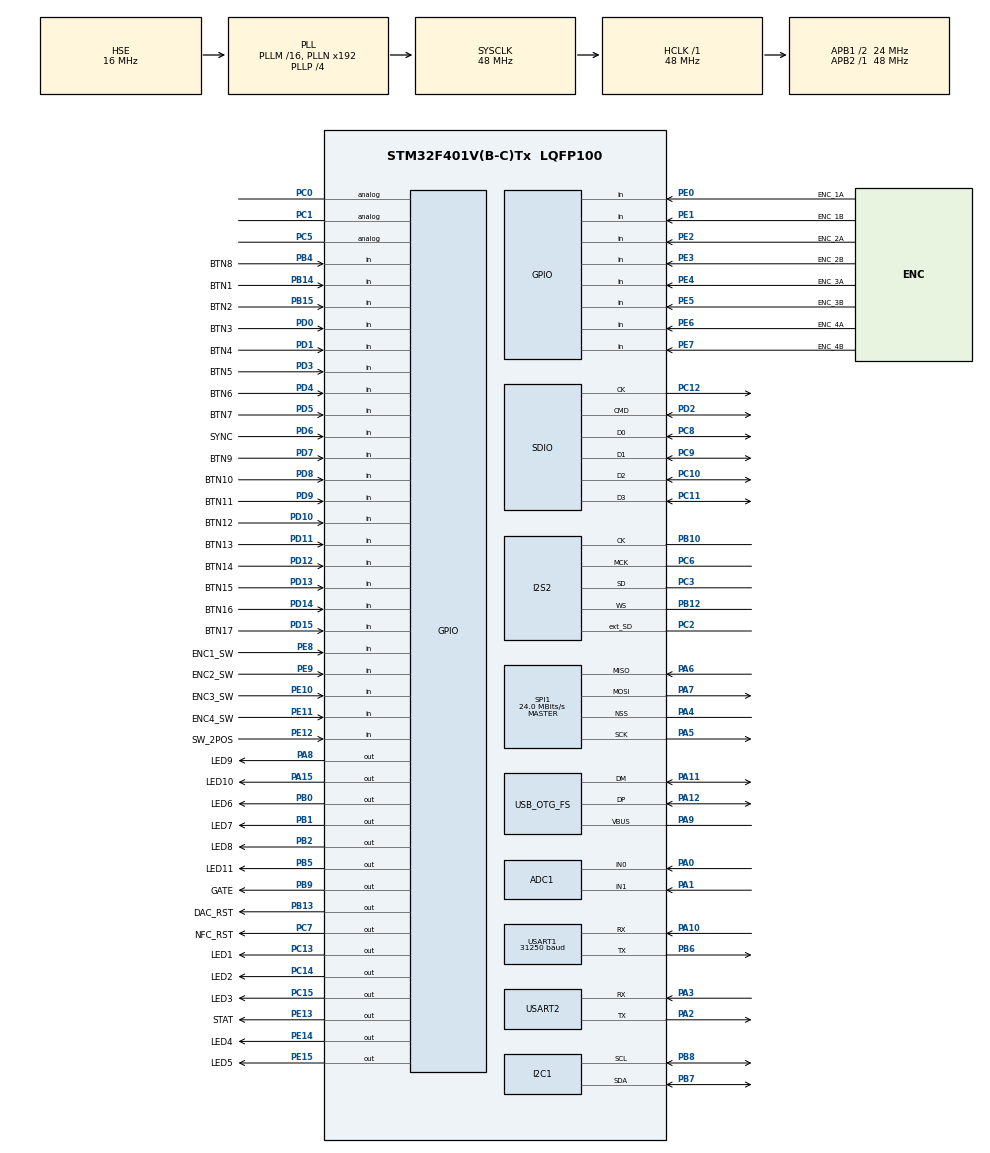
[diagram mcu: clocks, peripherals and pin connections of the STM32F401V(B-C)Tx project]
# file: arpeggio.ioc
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ADC1.Channel-0\#ChannelRegularConversion=ADC_CHANNEL_0
ADC1.Channel-1\#ChannelRegularConversion=ADC_CHANNEL_1
ADC1.ClockPrescaler=ADC_CLOCKPRESCALER_PCLK_DIV2
ADC1.ContinuousConvMode=DISABLE
ADC1.DMAContinuousRequests=DISABLE
ADC1.DataAlign=ADC_DATAALIGN_RIGHT
ADC1.DiscontinuousConvMode=DISABLE
ADC1.EOCSelection=EOC_SEQ_CONV
ADC1.EnableAnalogWatchDog=false
ADC1.ExternalTrigConvEdge=ADC_EXTERNALTRIGCONVEDGE_NONE
ADC1.InjNumberOfConversion=0
ADC1.NbrOfConversion=2
ADC1.NbrOfConversionFlag=1
ADC1.Rank-0\#ChannelRegularConversion=1
ADC1.Rank-1\#ChannelRegularConversion=2
ADC1.Resolution=ADC_RESOLUTION12b
ADC1.SamplingTime-0\#ChannelRegularConversion=ADC_SAMPLETIME_15CYCLES
ADC1.SamplingTime-1\#ChannelRegularConversion=ADC_SAMPLETIME_15CYCLES
ADC1.ScanConvMode=ENABLE
ADC1.master=1
Dma.ADC1.4.Channel=DMA_CHANNEL_0
Dma.ADC1.4.Direction=DMA_PERIPH_TO_MEMORY
Dma.ADC1.4.FIFOMode=DMA_FIFOMODE_DISABLE
Dma.ADC1.4.Instance=DMA2_Stream4
Dma.ADC1.4.MemDataAlignment=DMA_MDATAALIGN_HALFWORD
Dma.ADC1.4.MemInc=DMA_MINC_ENABLE
Dma.ADC1.4.Mode=DMA_CIRCULAR
Dma.ADC1.4.PeriphDataAlignment=DMA_PDATAALIGN_HALFWORD
Dma.ADC1.4.PeriphInc=DMA_PINC_DISABLE
Dma.ADC1.4.Priority=DMA_PRIORITY_MEDIUM
Dma.I2C1_RX.0.Channel=DMA_CHANNEL_1
Dma.I2C1_RX.0.Direction=DMA_PERIPH_TO_MEMORY
Dma.I2C1_RX.0.FIFOMode=DMA_FIFOMODE_DISABLE
Dma.I2C1_RX.0.Instance=DMA1_Stream0
Dma.I2C1_RX.0.MemDataAlignment=DMA_MDATAALIGN_BYTE
Dma.I2C1_RX.0.MemInc=DMA_MINC_ENABLE
Dma.I2C1_RX.0.Mode=DMA_NORMAL
Dma.I2C1_RX.0.PeriphDataAlignment=DMA_PDATAALIGN_BYTE
Dma.I2C1_RX.0.PeriphInc=DMA_PINC_DISABLE
Dma.I2C1_RX.0.Priority=DMA_PRIORITY_HIGH
Dma.I2C1_TX.1.Channel=DMA_CHANNEL_1
Dma.I2C1_TX.1.Direction=DMA_MEMORY_TO_PERIPH
Dma.I2C1_TX.1.FIFOMode=DMA_FIFOMODE_DISABLE
Dma.I2C1_TX.1.Instance=DMA1_Stream6
Dma.I2C1_TX.1.MemDataAlignment=DMA_MDATAALIGN_BYTE
Dma.I2C1_TX.1.MemInc=DMA_MINC_ENABLE
Dma.I2C1_TX.1.Mode=DMA_NORMAL
Dma.I2C1_TX.1.PeriphDataAlignment=DMA_PDATAALIGN_BYTE
Dma.I2C1_TX.1.PeriphInc=DMA_PINC_DISABLE
Dma.I2C1_TX.1.Priority=DMA_PRIORITY_HIGH
Dma.Request0=I2C1_RX
Dma.Request1=I2C1_TX
Dma.Request2=SPI1_RX
Dma.Request3=SPI1_TX
Dma.Request4=ADC1
Dma.SPI1_RX.2.Channel=DMA_CHANNEL_3
Dma.SPI1_RX.2.Direction=DMA_PERIPH_TO_MEMORY
Dma.SPI1_RX.2.FIFOMode=DMA_FIFOMODE_DISABLE
Dma.SPI1_RX.2.Instance=DMA2_Stream0
Dma.SPI1_RX.2.MemDataAlignment=DMA_MDATAALIGN_BYTE
Dma.SPI1_RX.2.MemInc=DMA_MINC_ENABLE
Dma.SPI1_RX.2.Mode=DMA_NORMAL
Dma.SPI1_RX.2.PeriphDataAlignment=DMA_PDATAALIGN_BYTE
Dma.SPI1_RX.2.PeriphInc=DMA_PINC_DISABLE
Dma.SPI1_RX.2.Priority=DMA_PRIORITY_HIGH
Dma.SPI1_TX.3.Channel=DMA_CHANNEL_3
Dma.SPI1_TX.3.Direction=DMA_MEMORY_TO_PERIPH
Dma.SPI1_TX.3.FIFOMode=DMA_FIFOMODE_DISABLE
Dma.SPI1_TX.3.Instance=DMA2_Stream3
Dma.SPI1_TX.3.MemDataAlignment=DMA_MDATAALIGN_BYTE
Dma.SPI1_TX.3.MemInc=DMA_MINC_ENABLE
Dma.SPI1_TX.3.Mode=DMA_NORMAL
Dma.SPI1_TX.3.PeriphDataAlignment=DMA_PDATAALIGN_BYTE
Dma.SPI1_TX.3.PeriphInc=DMA_PINC_DISABLE
Dma.SPI1_TX.3.Priority=DMA_PRIORITY_HIGH
FREERTOS.INCLUDE_vTaskDelayUntil=1
FREERTOS.Tasks01=defaultTask,0,128,StartDefaultTask
FREERTOS.configUSE_TIMERS=1
I2S2.AudioFreq=I2S_AUDIOFREQ_44K
I2S2.DataFormat=I2S_DATAFORMAT_16B
I2S2.ErrorAudioFreq=-3.33 %
I2S2.FullDuplexMode=I2S_FULLDUPLEXMODE_ENABLE
I2S2.RealAudioFreq=42.534 KHz
Mcu.Family=STM32F4
Mcu.Name=STM32F401V(B-C)Tx
Mcu.Package=LQFP100
NVIC.DMA1_Stream0_IRQn=true\:5\:0\:false
NVIC.DMA1_Stream6_IRQn=true\:5\:0\:false
NVIC.DMA2_Stream0_IRQn=true\:5\:0\:false
NVIC.DMA2_Stream3_IRQn=true\:5\:0\:false
NVIC.DMA2_Stream4_IRQn=true\:5\:0\:false
NVIC.OTG_FS_IRQn=true\:5\:0\:false
NVIC.PriorityGroup=NVIC_PRIORITYGROUP_4
NVIC.USART1_IRQn=true\:5\:0\:false
PA0-WKUP.Signal=ADCx_IN0
PA1.Signal=ADCx_IN1
PA10.Mode=Asynchronous
PA10.Signal=USART1_RX
PA11.Mode=Device_Only
PA11.Signal=USB_OTG_FS_DM
PA12.Mode=Device_Only
PA12.Signal=USB_OTG_FS_DP
PA13.Mode=Trace-Asynchronous_SW
PA13.Signal=SYS_JTMS-SWDIO
PA14.Mode=Trace-Asynchronous_SW
PA14.Signal=SYS_JTCK-SWCLK
PA15.GPIO_Label=LED10
PA15.GPIO_ModeDefaultOutputPP=GPIO_MODE_OUTPUT_PP
PA15.GPIO_PuPd=GPIO_NOPULL
PA15.GPIO_Speed=GPIO_SPEED_LOW
PA15.Signal=GPIO_Output
PA2.Mode=Asynchronous
PA2.Signal=USART2_TX
PA3.Mode=Asynchronous
PA3.Signal=USART2_RX
PA4.Mode=NSS_Signal_Hard
PA4.Signal=SPI1_NSS
PA5.Mode=Full_Duplex_Master
PA5.Signal=SPI1_SCK
PA6.Mode=Full_Duplex_Master
PA6.Signal=SPI1_MISO
PA7.Mode=Full_Duplex_Master
PA7.Signal=SPI1_MOSI
PA8.GPIO_Label=LED9
PA8.GPIO_ModeDefaultOutputPP=GPIO_MODE_OUTPUT_PP
PA8.GPIO_PuPd=GPIO_NOPULL
PA8.GPIO_Speed=GPIO_SPEED_LOW
PA8.Signal=GPIO_Output
PA9.Mode=Activate_VBUS
PA9.Signal=USB_OTG_FS_VBUS
PB0.GPIO_Label=LED6
PB0.GPIO_ModeDefaultOutputPP=GPIO_MODE_OUTPUT_PP
PB0.GPIO_PuPd=GPIO_NOPULL
PB0.GPIO_Speed=GPIO_SPEED_LOW
PB0.Signal=GPIO_Output
PB1.GPIO_Label=LED7
PB1.GPIO_ModeDefaultOutputPP=GPIO_MODE_OUTPUT_PP
PB1.GPIO_PuPd=GPIO_NOPULL
PB1.GPIO_Speed=GPIO_SPEED_LOW
PB1.Signal=GPIO_Output
PB10.Mode=Full_Duplex_Master
PB10.Signal=I2S2_CK
PB12.Mode=Full_Duplex_Master
PB12.Signal=I2S2_WS
PB13.GPIO_Label=DAC_RST
PB13.Signal=GPIO_Output
PB14.GPIO_Label=BTN1
PB14.Signal=GPIO_Input
PB15.GPIO_Label=BTN2
PB15.Signal=GPIO_Input
PB2.GPIO_Label=LED8
PB2.GPIO_ModeDefaultOutputPP=GPIO_MODE_OUTPUT_PP
PB2.GPIO_PuPd=GPIO_NOPULL
PB2.GPIO_Speed=GPIO_SPEED_LOW
PB2.Signal=GPIO_Output
PB3.Mode=Trace-Asynchronous_SW
PB3.Signal=SYS_JTDO-SWO
PB4.GPIO_Label=BTN8
PB4.Signal=GPIO_Input
PB5.GPIO_Label=LED11
PB5.GPIO_ModeDefaultOutputPP=GPIO_MODE_OUTPUT_PP
PB5.GPIO_PuPd=GPIO_NOPULL
PB5.GPIO_Speed=GPIO_SPEED_LOW
PB5.Signal=GPIO_Output
PB6.Mode=Asynchronous
PB6.Signal=USART1_TX
PB7.Mode=I2C
PB7.Signal=I2C1_SDA
PB8.Mode=I2C
PB8.Signal=I2C1_SCL
PB9.GPIO_Label=GATE
PB9.Signal=GPIO_Output
PC0.Signal=GPIO_Analog
PC1.Signal=GPIO_Analog
PC10.Mode=SD_4_bits_Wide_bus
PC10.Signal=SDIO_D2
PC11.Mode=SD_4_bits_Wide_bus
PC11.Signal=SDIO_D3
PC12.Mode=SD_4_bits_Wide_bus
PC12.Signal=SDIO_CK
PC13-ANTI_TAMP.GPIO_Label=LED1
PC13-ANTI_TAMP.GPIO_ModeDefaultOutputPP=GPIO_MODE_OUTPUT_PP
PC13-ANTI_TAMP.GPIO_PuPd=GPIO_NOPULL
PC13-ANTI_TAMP.GPIO_Speed=GPIO_SPEED_LOW
PC13-ANTI_TAMP.Signal=GPIO_Output
PC14-OSC32_IN.GPIO_Label=LED2
PC14-OSC32_IN.GPIO_ModeDefaultOutputPP=GPIO_MODE_OUTPUT_PP
PC14-OSC32_IN.GPIO_PuPd=GPIO_NOPULL
PC14-OSC32_IN.GPIO_Speed=GPIO_SPEED_LOW
PC14-OSC32_IN.Signal=GPIO_Output
PC15-OSC32_OUT.GPIO_Label=LED3
PC15-OSC32_OUT.GPIO_ModeDefaultOutputPP=GPIO_MODE_OUTPUT_PP
PC15-OSC32_OUT.GPIO_PuPd=GPIO_NOPULL
PC15-OSC32_OUT.GPIO_Speed=GPIO_SPEED_LOW
PC15-OSC32_OUT.Signal=GPIO_Output
PC2.Mode=Full_Duplex_Master
PC2.Signal=I2S2_ext_SD
PC3.Mode=Full_Duplex_Master
PC3.Signal=I2S2_SD
PC5.Signal=GPIO_Analog
PC6.Mode=Master_Clock_Activated
PC6.Signal=I2S2_MCK
PC7.GPIO_Label=NFC_RST
PC7.Signal=GPIO_Output
PC8.Mode=SD_4_bits_Wide_bus
PC8.Signal=SDIO_D0
PC9.Mode=SD_4_bits_Wide_bus
PC9.Signal=SDIO_D1
PD0.GPIO_Label=BTN3
PD0.Signal=GPIO_Input
PD1.GPIO_Label=BTN4
PD1.Signal=GPIO_Input
PD10.GPIO_Label=BTN12
PD10.Signal=GPIO_Input
PD11.GPIO_Label=BTN13
PD11.Signal=GPIO_Input
PD12.GPIO_Label=BTN14
PD12.Signal=GPIO_Input
PD13.GPIO_Label=BTN15
PD13.Signal=GPIO_Input
PD14.GPIO_Label=BTN16
PD14.Signal=GPIO_Input
PD15.GPIO_Label=BTN17
PD15.Signal=GPIO_Input
PD2.Mode=SD_4_bits_Wide_bus
PD2.Signal=SDIO_CMD
PD3.GPIO_Label=BTN5
PD3.Signal=GPIO_Input
PD4.GPIO_Label=BTN6
PD4.Signal=GPIO_Input
PD5.GPIO_Label=BTN7
PD5.Signal=GPIO_Input
PD6.GPIO_Label=SYNC
PD6.Signal=GPIO_Input
PD7.GPIO_Label=BTN9
PD7.Signal=GPIO_Input
PD8.GPIO_Label=BTN10
PD8.Signal=GPIO_Input
PD9.GPIO_Label=BTN11
PD9.Signal=GPIO_Input
PE0.GPIO_Label=ENC_1A
PE0.Signal=GPIO_Input
PE1.GPIO_Label=ENC_1B
PE1.Signal=GPIO_Input
PE10.GPIO_Label=ENC3_SW
PE10.Signal=GPIO_Input
PE11.GPIO_Label=ENC4_SW
PE11.Signal=GPIO_Input
PE12.GPIO_Label=SW_2POS
PE12.Signal=GPIO_Input
PE13.GPIO_Label=STAT
PE13.Signal=GPIO_Output
PE14.GPIO_Label=LED4
PE14.GPIO_ModeDefaultOutputPP=GPIO_MODE_OUTPUT_PP
PE14.GPIO_PuPd=GPIO_NOPULL
PE14.GPIO_Speed=GPIO_SPEED_LOW
PE14.Signal=GPIO_Output
PE15.GPIO_Label=LED5
PE15.GPIO_ModeDefaultOutputPP=GPIO_MODE_OUTPUT_PP
PE15.GPIO_PuPd=GPIO_NOPULL
PE15.GPIO_Speed=GPIO_SPEED_LOW
PE15.Signal=GPIO_Output
PE2.GPIO_Label=ENC_2A
PE2.Signal=GPIO_Input
PE3.GPIO_Label=ENC_2B
PE3.Signal=GPIO_Input
PE4.GPIO_Label=ENC_3A
PE4.Signal=GPIO_Input
PE5.GPIO_Label=ENC_3B
PE5.Signal=GPIO_Input
PE6.GPIO_Label=ENC_4A
PE6.Signal=GPIO_Input
PE7.GPIO_Label=ENC_4B
PE7.Signal=GPIO_Input
PE8.GPIO_Label=ENC1_SW
PE8.Signal=GPIO_Input
PE9.GPIO_Label=ENC2_SW
PE9.Signal=GPIO_Input
PH0\ -\ OSC_IN.Mode=HSE-External-Oscillator
PH0\ -\ OSC_IN.Signal=RCC_OSC_IN
PH1\ -\ OSC_OUT.Mode=HSE-External-Oscillator
PH1\ -\ OSC_OUT.Signal=RCC_OSC_OUT
ProjectManager.TargetToolchain=MDK-ARM V5
RCC.48MHZClocksFreq_Value=48000000
RCC.AHBFreq_Value=48000000
RCC.APB1CLKDivider=RCC_HCLK_DIV2
RCC.APB1Freq_Value=24000000
RCC.APB1TimFreq_Value=48000000
RCC.APB2Freq_Value=48000000
RCC.APB2TimFreq_Value=48000000
RCC.CortexFreq_Value=48000000
RCC.HCLKFreq_Value=48000000
RCC.HSE_VALUE=16000000
RCC.HSI_VALUE=16000000
RCC.LSE_VALUE=32768
RCC.PLLI2SN=196
RCC.PLLP=RCC_PLLP_DIV4
RCC.SYSCLKFreq_VALUE=48000000
RCC.SYSCLKSource=RCC_SYSCLKSOURCE_PLLCLK
RCC.VCOOutputFreq_Value=192000000
SDIO.BusWide=SDIO_BUS_WIDE_1B
SDIO.WideMode=SDIO_BUS_WIDE_4B
SH.ADCx_IN0.0=ADC1_IN0,IN0
SH.ADCx_IN1.0=ADC1_IN1,IN1
SPI1.BaudRatePrescaler=SPI_BAUDRATEPRESCALER_2
SPI1.CalculateBaudRate=24.0 MBits/s
SPI1.Mode=SPI_MODE_MASTER
SPI1.VirtualNSS=VM_NSSHARD
USART1.BaudRate=31250
USB_DEVICE.MANUFACTURER_STRING=Tangible Instruments
USB_DEVICE.PRODUCT_STRING_AUDIO_FS=Arpeggio
USB_DEVICE.USBD_DEBUG_LEVEL=2
USB_DEVICE.USBD_HandleTypeDef=hUsbDeviceFS
USB_DEVICE.VirtualMode=Audio
USB_OTG_FS.VirtualMode=Device_Only
VP_FATFS_VS_SDIO.Mode=SDIO
VP_FREERTOS_VS_ENABLE.Mode=Enabled
VP_USB_DEVICE_VS_USB_DEVICE_AUDIO_FS.Mode=AUDIO_FS
board=arpeggio

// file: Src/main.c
/**
  ******************************************************************************
  * File Name          : main.c
  * Description        : Main program body
  ******************************************************************************
  *
  * COPYRIGHT(c) 2016 STMicroelectronics
  *
  * Redistribution and use in source and binary forms, with or without modification,
  * are permitted provided that the following conditions are met:
  *   1. Redistributions of source code must retain the above copyright notice,
  *      this list of conditions and the following disclaimer.
  *   2. Redistributions in binary form must reproduce the above copyright notice,
  *      this list of conditions and the following disclaimer in the documentation
  *      and/or other materials provided with the distribution.
  *   3. Neither the name of STMicroelectronics nor the names of its contributors
  *      may be used to endorse or promote products derived from this software
  *      without specific prior written permission.
  *
  * THIS SOFTWARE IS PROVIDED BY THE COPYRIGHT HOLDERS AND CONTRIBUTORS "AS IS"
  * AND ANY EXPRESS OR IMPLIED WARRANTIES, INCLUDING, BUT NOT LIMITED TO, THE
  * IMPLIED WARRANTIES OF MERCHANTABILITY AND FITNESS FOR A PARTICULAR PURPOSE ARE
  * DISCLAIMED. IN NO EVENT SHALL THE COPYRIGHT HOLDER OR CONTRIBUTORS BE LIABLE
  * FOR ANY DIRECT, INDIRECT, INCIDENTAL, SPECIAL, EXEMPLARY, OR CONSEQUENTIAL
  * DAMAGES (INCLUDING, BUT NOT LIMITED TO, PROCUREMENT OF SUBSTITUTE GOODS OR
  * SERVICES; LOSS OF USE, DATA, OR PROFITS; OR BUSINESS INTERRUPTION) HOWEVER
  * CAUSED AND ON ANY THEORY OF LIABILITY, WHETHER IN CONTRACT, STRICT LIABILITY,
  * OR TORT (INCLUDING NEGLIGENCE OR OTHERWISE) ARISING IN ANY WAY OUT OF THE USE
  * OF THIS SOFTWARE, EVEN IF ADVISED OF THE POSSIBILITY OF SUCH DAMAGE.
  *
  ******************************************************************************
  */
#include "stm32f4xx_hal.h"
#include "cmsis_os.h"
#include "adc.h"
#include "dma.h"
#include "fatfs.h"
#include "i2c.h"
#include "i2s.h"
#include "sdio.h"
#include "spi.h"
#include "usart.h"
#include "usb_device.h"
#include "gpio.h"

/* USER CODE BEGIN Includes */
#include <stdlib.h>
#include <stdio.h>

/* USER CODE END Includes */

/* USER CODE BEGIN PV */
/* Private variables ---------------------------------------------------------*/

/* The next six lines are related to printf debugging on ITM stimulus port 0 */
#define ITM_Port8(n)    (*((volatile unsigned char *)(0xE0000000+4*n)))
#define ITM_Port16(n)   (*((volatile unsigned short*)(0xE0000000+4*n)))
#define ITM_Port32(n)   (*((volatile unsigned long *)(0xE0000000+4*n)))
#define DEMCR           (*((volatile unsigned long *)(0xE000EDFC)))
#define TRCENA          0x01000000

struct __FILE { int handle; /* Add whatever needed */ };
FILE __stdout;
FILE __stdin;

/* USER CODE END PV */

void SystemClock_Config(void);
void MX_FREERTOS_Init(void);

/* USER CODE BEGIN PFP */
/* Private function prototypes -----------------------------------------------*/

/* USER CODE END PFP */

int main(void)
{

  /* MCU Configuration----------------------------------------------------------*/

  /* Reset of all peripherals, Initializes the Flash interface and the Systick. */
  HAL_Init();

  /* Configure the system clock */
  SystemClock_Config();

  /* Initialize all configured peripherals */
  MX_GPIO_Init();
  MX_DMA_Init();
  MX_ADC1_Init();
  MX_I2C1_Init();
  MX_I2S2_Init();
  MX_SDIO_SD_Init();
  MX_SPI1_Init();
  MX_USART1_UART_Init();
  MX_USART2_UART_Init();

  /* Call init function for freertos objects (in freertos.c) */
  MX_FREERTOS_Init();

  /* Start scheduler */
  osKernelStart();

  /* We should never get here as control is now taken by the scheduler */

  /* Infinite loop */
  while (1)
  {

  }

}

/** System Clock Configuration
*/
void SystemClock_Config(void)
{

  RCC_OscInitTypeDef RCC_OscInitStruct;
  RCC_ClkInitTypeDef RCC_ClkInitStruct;
  RCC_PeriphCLKInitTypeDef PeriphClkInitStruct;

  __PWR_CLK_ENABLE();

  __HAL_PWR_VOLTAGESCALING_CONFIG(PWR_REGULATOR_VOLTAGE_SCALE2);

  RCC_OscInitStruct.OscillatorType = RCC_OSCILLATORTYPE_HSE;
  RCC_OscInitStruct.HSEState = RCC_HSE_ON;
  RCC_OscInitStruct.PLL.PLLState = RCC_PLL_ON;
  RCC_OscInitStruct.PLL.PLLSource = RCC_PLLSOURCE_HSE;
  RCC_OscInitStruct.PLL.PLLM = 16;
  RCC_OscInitStruct.PLL.PLLN = 192;
  RCC_OscInitStruct.PLL.PLLP = RCC_PLLP_DIV4;
  RCC_OscInitStruct.PLL.PLLQ = 4;
  HAL_RCC_OscConfig(&RCC_OscInitStruct);

  RCC_ClkInitStruct.ClockType = RCC_CLOCKTYPE_SYSCLK|RCC_CLOCKTYPE_PCLK1;
  RCC_ClkInitStruct.SYSCLKSource = RCC_SYSCLKSOURCE_PLLCLK;
  RCC_ClkInitStruct.AHBCLKDivider = RCC_SYSCLK_DIV1;
  RCC_ClkInitStruct.APB1CLKDivider = RCC_HCLK_DIV2;
  RCC_ClkInitStruct.APB2CLKDivider = RCC_HCLK_DIV1;
  HAL_RCC_ClockConfig(&RCC_ClkInitStruct, FLASH_LATENCY_1);

  PeriphClkInitStruct.PeriphClockSelection = RCC_PERIPHCLK_I2S;
  PeriphClkInitStruct.PLLI2S.PLLI2SN = 196;
  PeriphClkInitStruct.PLLI2S.PLLI2SR = 2;
  HAL_RCCEx_PeriphCLKConfig(&PeriphClkInitStruct);

  HAL_SYSTICK_Config(HAL_RCC_GetHCLKFreq()/1000);

  HAL_SYSTICK_CLKSourceConfig(SYSTICK_CLKSOURCE_HCLK);

  /* SysTick_IRQn interrupt configuration */
  HAL_NVIC_SetPriority(SysTick_IRQn, 15, 0);
}

/* USER CODE BEGIN 4 */
int fputc(int ch, FILE *f) {
  if (DEMCR & TRCENA) {
    while (ITM_Port32(0) == 0);
    ITM_Port8(0) = ch;
  }
  return(ch);
}

/* USER CODE END 4 */

#ifdef USE_FULL_ASSERT

/**
   * @brief Reports the name of the source file and the source line number
   * where the assert_param error has occurred.
   * @param file: pointer to the source file name
   * @param line: assert_param error line source number
   * @retval None
   */
void assert_failed(uint8_t* file, uint32_t line)
{
  /* USER CODE BEGIN 6 */
  /* User can add his own implementation to report the file name and line number,
    ex: printf("Wrong parameters value: file %s on line %d\r\n", file, line) */
	printf("Wrong parameters value: file %s on line %d\r\n", file, line);
  /* USER CODE END 6 */

}

#endif

/************************ (C) COPYRIGHT STMicroelectronics *****END OF FILE****/

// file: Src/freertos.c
/**
  ******************************************************************************
  * File Name          : freertos.c
  * Description        : Code for freertos applications
  ******************************************************************************
  *
  * COPYRIGHT(c) 2016 STMicroelectronics
  *
  * Redistribution and use in source and binary forms, with or without modification,
  * are permitted provided that the following conditions are met:
  *   1. Redistributions of source code must retain the above copyright notice,
  *      this list of conditions and the following disclaimer.
  *   2. Redistributions in binary form must reproduce the above copyright notice,
  *      this list of conditions and the following disclaimer in the documentation
  *      and/or other materials provided with the distribution.
  *   3. Neither the name of STMicroelectronics nor the names of its contributors
  *      may be used to endorse or promote products derived from this software
  *      without specific prior written permission.
  *
  * THIS SOFTWARE IS PROVIDED BY THE COPYRIGHT HOLDERS AND CONTRIBUTORS "AS IS"
  * AND ANY EXPRESS OR IMPLIED WARRANTIES, INCLUDING, BUT NOT LIMITED TO, THE
  * IMPLIED WARRANTIES OF MERCHANTABILITY AND FITNESS FOR A PARTICULAR PURPOSE ARE
  * DISCLAIMED. IN NO EVENT SHALL THE COPYRIGHT HOLDER OR CONTRIBUTORS BE LIABLE
  * FOR ANY DIRECT, INDIRECT, INCIDENTAL, SPECIAL, EXEMPLARY, OR CONSEQUENTIAL
  * DAMAGES (INCLUDING, BUT NOT LIMITED TO, PROCUREMENT OF SUBSTITUTE GOODS OR
  * SERVICES; LOSS OF USE, DATA, OR PROFITS; OR BUSINESS INTERRUPTION) HOWEVER
  * CAUSED AND ON ANY THEORY OF LIABILITY, WHETHER IN CONTRACT, STRICT LIABILITY,
  * OR TORT (INCLUDING NEGLIGENCE OR OTHERWISE) ARISING IN ANY WAY OUT OF THE USE
  * OF THIS SOFTWARE, EVEN IF ADVISED OF THE POSSIBILITY OF SUCH DAMAGE.
  *
  ******************************************************************************
  */

#include "FreeRTOS.h"
#include "task.h"
#include "cmsis_os.h"

/* USER CODE BEGIN Includes */
//#include "stm32f4xx_hal.h"
#include "event.h"
#include "encoder.h"
#include "adc.h"
/* USER CODE END Includes */

osThreadId defaultTaskHandle;

/* USER CODE BEGIN Variables */
typedef enum {
    UP = 0,
    UPDOWN,
    DOWN,
    DOWNUP,
    SEQ,
    RND
} arp_mode_type
;
struct encoder *enc1;
struct encoder *enc2;
struct encoder *enc3;
struct encoder *enc4;
uint16_t adc1_values[2];
arp_mode_type arp_mode;

xQueueHandle event_queue;

/* USER CODE END Variables */

void StartDefaultTask(void const * argument);

extern void MX_FATFS_Init(void);
extern void MX_USB_DEVICE_Init(void);
void MX_FREERTOS_Init(void); /* (MISRA C 2004 rule 8.1) */

/* USER CODE BEGIN FunctionPrototypes */
void vFrontPanelInputHandler( void *pvParameters );
void vKeyboardMode( void *pvParameters );

/* USER CODE END FunctionPrototypes */

/* Hook prototypes */

/* Init FreeRTOS */

void MX_FREERTOS_Init(void) {
  /* USER CODE BEGIN Init */

	/* init code for FATFS */
  //MX_FATFS_Init();
  /* init code for USB_DEVICE */
  //MX_USB_DEVICE_Init();
	/* Initialize all external devices */

	/* Initialize encoders */
	enc1 = encoder_init(1, ENC_1A_GPIO_Port, ENC_1A_Pin, ENC_1B_GPIO_Port, ENC_1B_Pin,
											ENC1_SW_GPIO_Port, ENC1_SW_Pin);
	enc2 = encoder_init(1, ENC_2A_GPIO_Port, ENC_2A_Pin, ENC_2B_GPIO_Port, ENC_2B_Pin,
											ENC2_SW_GPIO_Port, ENC2_SW_Pin);
	enc3 = encoder_init(1, ENC_3A_GPIO_Port, ENC_3A_Pin, ENC_3B_GPIO_Port, ENC_3B_Pin,
											ENC3_SW_GPIO_Port, ENC3_SW_Pin);
	enc4 = encoder_init(1, ENC_4A_GPIO_Port, ENC_4A_Pin, ENC_4B_GPIO_Port, ENC_4B_Pin,
											ENC4_SW_GPIO_Port, ENC4_SW_Pin);

  /* USER CODE END Init */

  /* Create the thread(s) */
  /* definition and creation of defaultTask */
  osThreadDef(defaultTask, StartDefaultTask, osPriorityNormal, 0, 128);
  defaultTaskHandle = osThreadCreate(osThread(defaultTask), NULL);

  /* USER CODE BEGIN RTOS_THREADS */
  xTaskCreate(vFrontPanelInputHandler, "IH_FPI", configMINIMAL_STACK_SIZE, NULL, 5, NULL );
	xTaskCreate(vKeyboardMode, "MODE_KBRD", configMINIMAL_STACK_SIZE, NULL, 5, NULL);
  /* USER CODE END RTOS_THREADS */

  /* USER CODE BEGIN RTOS_QUEUES */
  /* add queues, ... */
	event_queue = xQueueCreate( 10, sizeof(struct event));
	if (event_queue == NULL)
	{
		printf("Insufficient heap space available to create queue 'event_queue.'\r\n");
	}
	else
	{
		printf("Successfully created queue 'event_queue' with handle %d.\r\n", event_queue);
	}
  /* USER CODE END RTOS_QUEUES */
}

/* StartDefaultTask function */
void StartDefaultTask(void const * argument)
{
  /* init code for FATFS */
  //MX_FATFS_Init();

  /* init code for USB_DEVICE */
  //MX_USB_DEVICE_Init();

  for(;;)
  {
    osDelay(1);
  }
}

/* USER CODE BEGIN Application */
void vFrontPanelInputHandler( void *pvParameters )
{
	TickType_t xLastExecutionTime;
	xLastExecutionTime = xTaskGetTickCount();
	static uint32_t fpi_bs_new = 0;
	static uint32_t fpi_bs_old = 0;
	static struct event *ev = NULL;
	const portTickType ticks_to_wait = 1/portTICK_RATE_MS;
	uint8_t enc_state;
	portBASE_TYPE xStatus;

	if(ev == NULL){ev = event_create(ALL_EVENTS);}
	for( ;; )
	{
		/* Start ADC Conversion */
		//HAL_ADC_Start_DMA(&hadc1, (uint32_t *)adc1_values, 2);
		/* Read button states */
		fpi_bs_new |= ((HAL_GPIO_ReadPin(BTN1_GPIO_Port,  BTN1_Pin)  == 1) ? 1UL : 0UL)     ;
		fpi_bs_new |= ((HAL_GPIO_ReadPin(BTN2_GPIO_Port,  BTN2_Pin)  == 1) ? 1UL : 0UL) << 1;
		fpi_bs_new |= ((HAL_GPIO_ReadPin(BTN3_GPIO_Port,  BTN3_Pin)  == 1) ? 1UL : 0UL) << 2;
		fpi_bs_new |= ((HAL_GPIO_ReadPin(BTN4_GPIO_Port,  BTN4_Pin)  == 1) ? 1UL : 0UL) << 3;
		fpi_bs_new |= ((HAL_GPIO_ReadPin(BTN5_GPIO_Port,  BTN5_Pin)  == 1) ? 1UL : 0UL) << 4;
		fpi_bs_new |= ((HAL_GPIO_ReadPin(BTN6_GPIO_Port,  BTN6_Pin)  == 1) ? 1UL : 0UL) << 5;
		fpi_bs_new |= ((HAL_GPIO_ReadPin(BTN7_GPIO_Port,  BTN7_Pin)  == 1) ? 1UL : 0UL) << 6;
		fpi_bs_new |= ((HAL_GPIO_ReadPin(BTN8_GPIO_Port,  BTN8_Pin)  == 1) ? 1UL : 0UL) << 7;
		fpi_bs_new |= ((HAL_GPIO_ReadPin(BTN9_GPIO_Port,  BTN9_Pin)  == 1) ? 1UL : 0UL) << 8;
		fpi_bs_new |= ((HAL_GPIO_ReadPin(BTN10_GPIO_Port, BTN10_Pin) == 1) ? 1UL : 0UL) << 9;
		fpi_bs_new |= ((HAL_GPIO_ReadPin(BTN11_GPIO_Port, BTN11_Pin) == 1) ? 1UL : 0UL) << 10;
		fpi_bs_new |= ((HAL_GPIO_ReadPin(BTN12_GPIO_Port, BTN12_Pin) == 1) ? 1UL : 0UL) << 11;
		fpi_bs_new |= ((HAL_GPIO_ReadPin(BTN13_GPIO_Port, BTN13_Pin) == 1) ? 1UL : 0UL) << 12;
		fpi_bs_new |= ((HAL_GPIO_ReadPin(BTN14_GPIO_Port, BTN14_Pin) == 1) ? 1UL : 0UL) << 13;
		fpi_bs_new |= ((HAL_GPIO_ReadPin(BTN15_GPIO_Port, BTN15_Pin) == 1) ? 1UL : 0UL) << 14;
		fpi_bs_new |= ((HAL_GPIO_ReadPin(BTN16_GPIO_Port, BTN16_Pin) == 1) ? 1UL : 0UL) << 15;
		fpi_bs_new |= ((HAL_GPIO_ReadPin(BTN17_GPIO_Port, BTN17_Pin) == 1) ? 1UL : 0UL) << 16;
		fpi_bs_new |= ((HAL_GPIO_ReadPin(ENC1_SW_GPIO_Port, ENC1_SW_Pin) == 1) ? 1UL : 0UL) << 17;
		fpi_bs_new |= ((HAL_GPIO_ReadPin(ENC2_SW_GPIO_Port, ENC2_SW_Pin) == 1) ? 1UL : 0UL) << 18;
		fpi_bs_new |= ((HAL_GPIO_ReadPin(ENC3_SW_GPIO_Port, ENC3_SW_Pin) == 1) ? 1UL : 0UL) << 19;
		fpi_bs_new |= ((HAL_GPIO_ReadPin(ENC4_SW_GPIO_Port, ENC4_SW_Pin) == 1) ? 1UL : 0UL) << 20;
		/*Read 2-position switch */
		fpi_bs_new |= ((HAL_GPIO_ReadPin(SW_2POS_GPIO_Port, SW_2POS_Pin) == 1) ? 1UL : 0UL) << 21;
		if(fpi_bs_new != fpi_bs_old)
		{
			for(uint8_t i = 0; i < 23; i++)
			{
				if((fpi_bs_new & (1UL << (i))) != (fpi_bs_old &(1UL << (i))))
				{
					//Generate button press/release event. Add to event queue.
					event_set_type(ev, BUTTON_INPUT);
					event_add_data(event_wrap_data(EVENT_UINT8_T, (void *)i), 0, ev); /* Add button number to event data array */
					event_add_data(event_wrap_data(EVENT_UINT8_T,(void *)(fpi_bs_new & (1UL << i))), 1, ev); /* Add button state to event data array */
					printf("Writing to queue 'event_queue' with handle %d.\r\n",event_queue);
					xStatus = xQueueSend(event_queue, ev, ticks_to_wait);
					if (xStatus != pdPASS)
					{
						printf("Could not add event to queue 'event_queue.' \r\n");
					}
				}
			}
		}
		/* Read encoder values */
		enc_state = encoder_read(enc1);
		if(enc_state != 0)
		{
			event_set_type(ev, ENC_INPUT);
			event_add_data(event_wrap_data(EVENT_UINT8_T, (void *)1) , 0, ev);
			event_add_data(event_wrap_data(EVENT_INT8_T, (void *)enc_state) , 1, ev);
			xQueueSend(event_queue, ev, ticks_to_wait);
		}
		enc_state = encoder_read(enc2);
		if(enc_state != 0)
		{
			event_set_type(ev, ENC_INPUT);
			event_add_data(event_wrap_data(EVENT_UINT8_T, (void *)2) , 0, ev);
			event_add_data(event_wrap_data(EVENT_INT8_T, (void *)enc_state) , 1, ev);
			xQueueSend(event_queue, ev, ticks_to_wait);
		}
		enc_state = encoder_read(enc3);
		if(enc_state != 0)
		{
			event_set_type(ev, ENC_INPUT);
			event_add_data(event_wrap_data(EVENT_UINT8_T, (void *)3) , 0, ev);
			event_add_data(event_wrap_data(EVENT_INT8_T, (void *)enc_state) , 1, ev);
			xQueueSend(event_queue, ev, ticks_to_wait);
		}
		enc_state = encoder_read(enc4);
		if(enc_state != 0)
		{
			event_set_type(ev, ENC_INPUT);
			event_add_data(event_wrap_data(EVENT_UINT8_T, (void *)4) , 0, ev);
			event_add_data(event_wrap_data(EVENT_INT8_T, (void *)enc_state) , 1, ev);
			xQueueSend(event_queue, ev, ticks_to_wait);
		}

		/*Read slide potentiometer */
//		static uint8_t index;
//		for(index = 0; index<2; index++){
//			printf("\r\n ADC value on ch%d = %d\r\n", index, adc1_values[index]);
//		}

		/*Read rotary potentiometer */

		vTaskDelayUntil( &xLastExecutionTime, 20/portTICK_RATE_MS); // ~50Hz refresh rate
		// Perform action here.
	}
	vTaskDelete( NULL ); /* Normal execution should never reach this line */
}

void vKeyboardMode ( void *pvParameters )
{
	struct event n_event;
	portBASE_TYPE xStatus;
	const portTickType xTicksToWait = 1 / portTICK_RATE_MS;

	for( ;; )
	{
		/* Check for new events */
		xStatus = xQueueReceive(event_queue, &n_event, xTicksToWait);
			if(xStatus == pdPASS)
			{
				switch (n_event.type)
				{
					case ALL_EVENTS:
						printf("\r\nUninitialized event received on event queue.\r\n");
					case BUTTON_INPUT:
						taskENTER_CRITICAL();
						printf("\r\nReceived event of type ");
						printf("BUTTON_INPUT.\r\n");
					  printf("\tData Payload:\r\n");
						printf("\t\tButton: %d\r\n", (uint8_t)n_event.data[0].data.uint8_v);
					  printf("\t\tAction: %s\r\n", (n_event.data[1].data.uint8_v == 1 ? "PRESS" : "RELEASE"));
						taskEXIT_CRITICAL();
						break;
					case ENC_INPUT:
						taskENTER_CRITICAL();
						printf("\r\nReceived event of type ");
						printf("ENC_INPUT.\r\n");
					  printf("\tData Payload:\r\n");
						printf("\t\tEncoder: %d\r\n", (uint8_t)n_event.data[0].data.uint8_v);
					  printf("\t\tAction: %s\r\n", (n_event.data[1].data.int8_v == 1 ? "LEFT" : "RIGHT"));
						taskEXIT_CRITICAL();
						break;
					default:
						printf("Unrecognized event type received on event queue.\r\n");
						break;
				}
			}
			else
			{
				// Event buffer is currently empty.
			}
	}
	vTaskDelete( NULL ); /* Normal execution should never reach this line */
}

/* USER CODE END Application */

/************************ (C) COPYRIGHT STMicroelectronics *****END OF FILE****/
